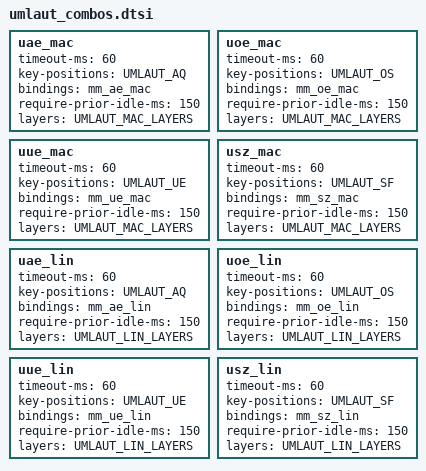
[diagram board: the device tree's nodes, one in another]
uae_mac: uae_mac {
    timeout-ms = <60>;
    key-positions = UMLAUT_AQ;
    bindings = <&mm_ae_mac>;
    require-prior-idle-ms = <150>;
    layers = UMLAUT_MAC_LAYERS;
};
uoe_mac: uoe_mac {
    timeout-ms = <60>;
    key-positions = UMLAUT_OS;
    bindings = <&mm_oe_mac>;
    require-prior-idle-ms = <150>;
    layers = UMLAUT_MAC_LAYERS;
};
uue_mac: uue_mac {
    timeout-ms = <60>;
    key-positions = UMLAUT_UE;
    bindings = <&mm_ue_mac>;
    require-prior-idle-ms = <150>;
    layers = UMLAUT_MAC_LAYERS;
};
usz_mac: usz_mac {
    timeout-ms = <60>;
    key-positions = UMLAUT_SF;
    bindings = <&mm_sz_mac>;
    require-prior-idle-ms = <150>;
    layers = UMLAUT_MAC_LAYERS;
};
uae_lin: uae_lin {
    timeout-ms = <60>;
    key-positions = UMLAUT_AQ;
    bindings = <&mm_ae_lin>;
    require-prior-idle-ms = <150>;
    layers = UMLAUT_LIN_LAYERS;
};
uoe_lin: uoe_lin {
    timeout-ms = <60>;
    key-positions = UMLAUT_OS;
    bindings = <&mm_oe_lin>;
    require-prior-idle-ms = <150>;
    layers = UMLAUT_LIN_LAYERS;
};
uue_lin: uue_lin {
    timeout-ms = <60>;
    key-positions = UMLAUT_UE;
    bindings = <&mm_ue_lin>;
    require-prior-idle-ms = <150>;
    layers = UMLAUT_LIN_LAYERS;
};
usz_lin: usz_lin {
    timeout-ms = <60>;
    key-positions = UMLAUT_SF;
    bindings = <&mm_sz_lin>;
    require-prior-idle-ms = <150>;
    layers = UMLAUT_LIN_LAYERS;
};
